# AT32F421xx register map
Vendor: Keil; Series: AT32F421; File version: 1.0
ARM 32-bit Cortex-M4 Microcontroller based device, CPU clock up to 120MHz, etc.
CPU: CM4 r0p1, little endian, no MPU, FPU, 4 interrupt priority bits
Registers are 32-bit, read-write, reset 0x0 unless marked. A register's access mark holds for its fields unless they carry their own. Offsets are from the block's base; lines under a group give offsets from that group; [hi:lo] are bit positions; {n}, {i} and the like mark numbered series; 'fields as' and 'values as' point back to an identical list; <NAME> marks a mode.

## Memory map
0x40000400 TMR3 size 0x400 — General purpose timer
0x40001000 TMR6 size 0x400 — Basic timer
0x40002000 TMR14 size 0x400 — General-purpose-timers
0x40002800 ERTC size 0x400 — Real-time clock
0x40002C00 WWDG size 0x400 — Window watchdog
0x40003000 IWDG size 0x400 — Independent watchdog
0x40003800 SPI2 size 0x400
0x40004400 USART2 size 0x400
0x40005400 I2C1 size 0x400 — Inter integrated circuit
0x40005800 I2C2 size 0x400
0x40007000 PWR size 0x400 — Power control
0x40010000 SYSCFG size 0x400 — System configuration controller
0x4001001C COMP size 0x400 — Compare
0x40010400 EXTI size 0x400
0x40012400 ADC1 size 0x400 — Analog to digital converter
0x40012C00 TMR1 size 0x400 — Advanced timer
0x40013000 SPI1 size 0x400 — Serial peripheral interface
0x40013800 USART1 size 0x400 — Universal synchronous asynchronous receiver transmitter
0x40014000 TMR15 size 0x400 — General-purpose-timers
0x40014400 TMR16 size 0x400 — General-purpose-timers
0x40014800 TMR17 size 0x400
0x40020000 DMA1 size 0x400 — DMA controller
0x40021000 RCC size 0x400 — Reset and clock control
0x40022000 EFC size 0x400
0x40023000 CRC size 0x400 — CRC calculation unit
0x48000000 GPIOA size 0x400 — General purpose I/Os
0x48000400 GPIOB size 0x400
0x48000800 GPIOC size 0x400
0x48001400 GPIOF size 0x400
0xE000E000 NVIC size 0x1001 — Nested Vectored Interrupt Controller
0xE0042000 MCUDBG size 0x400 — Debug support

## Interrupts
0 WWDG — Window Watchdog interrupt
1 PVD (PWR) — PVD through EXTI line detection interrupt
2 ERTC_WKUP (ERTC) — ERTC Global interrupt through the EXTI line17/19/21
3 EFLASH (EFC) — EFlash global interrupt
4 RCC — RCC global interrupt
5 EXTINT1_0 (EXTI) — EXTI Line1-0 interrupt
6 EXTINT3_2 (EXTI) — EXTI Line3-2 interrupt
7 EXTINT15_4 (EXTI) — EXTI Line15-4 interrupt
9 DMA1_Channel1 (DMA1) — DMA1 Channel1 global interrupt
10 DMA1_Channel3_2 (DMA1) — DMA1 Channel3-2 global interrupt
11 DMA1_Channel5_4 (DMA1) — DMA1 Channel5-4 global interrupt
12 ADC_COMP (ADC1, COMP) — ADC and COMP global interrupt
13 TMR1_BRK_UP_TRG_COM (TMR1) — TMR1 Break Update Trigger and Communication global
14 TIM1_CC (TMR1) — TMR1 Capture Compare interrupt
16 TMR3 — TMR3 global interrupt
17 TMR6 — TMR6 global interrupt
19 TMR14 — TMR14 global interrupt
20 TMR15 — TMR15 global interrupt
21 TMR16 — TMR16 global interrupt
22 TMR17 — TMR17 global interrupt
23 I2C1_EV (I2C1) — I2C1 event interrupt
24 I2C2_EV (I2C2) — I2C2 event interrupt
25 SPI1 — SPI1 global interrupt
26 SPI2 — SPI2 global interrupt
27 USART1 — USART1 global interrupt
28 USART2 — USART2 global interrupt
32 I2C1_ER (I2C1) — I2C1 error interrupt
34 I2C2_ER (I2C2) — I2C2 error interrupt

## PWR — Power control
Base 0x40007000
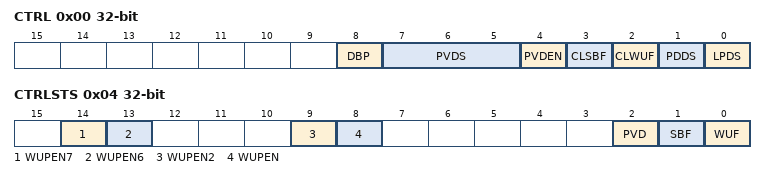
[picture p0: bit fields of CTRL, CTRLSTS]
0x00 CTRL — Power control register (PWR_CTRL)
  [8] DBP — Disable Backup Domain write protection
  [7:5] PVDS — PVD Level Selection
  [4] PVDEN — Power Voltage Detector Enable
  [3] CLSBF — Clear STANDBY Flag
  [2] CLWUF — Clear Wake-up Flag
  [1] PDDS — Power Down Deep Sleep
  [0] LPDS — Low Power Deep Sleep
0x04 CTRLSTS — Power control register (PWR_CTRLST)
  [14] WUPEN7 — Enable WKUP7 pin
  [13] WUPEN6 — Enable WKUP6 pin
  [9] WUPEN2 — Enable WKUP2 pin
  [8] WUPEN — Enable WKUP pin
  [2] PVD ro — PVD Output
  [1] SBF ro — STANDBY Flag
  [0] WUF ro — Wake-Up Flag
0x20 CTRL2 — Power control register 2 (PWR_CTRL2)
  [5] LPDS1 — Low Power Deep Sleep bit 1

## Licence text in the file
ARM Limited (ARM) is supplying this software for use with Cortex-M processor based microcontroller, but can be equally used for other suitable processor architectures. This file can be freely distributed. Modifications to this file shall be clearly marked. . THIS SOFTWARE IS PROVIDED "AS IS". NO WARRANTIES, WHETHER EXPRESS, IMPLIED. OR STATUTORY, INCLUDING, BUT NOT LIMITED TO, IMPLIED WARRANTIES OF. MERCHANTABILITY AND FITNESS FOR A PARTICULAR PURPOSE APPLY TO THIS SOFTWARE. ARM SHALL NOT, IN ANY CIRCUMSTANCES, BE LIABLE FOR SPECIAL, INCIDENTAL, OR. CONSEQUENTIAL DAMAGES, FOR ANY REASON WHATSOEVER.

## Notices in the file
Copyright (C) 2012-2014 ARM Limited. All rights reserved.
Purpose: System Viewer Description (SVD) Example (Schema Version 1.1)
This is a description of a none-existent and incomplete device
for demonstration purposes only.
Redistribution and use in source and binary forms, with or without
modification, are permitted provided that the following conditions are met:
- Redistributions of source code must retain the above copyright
notice, this list of conditions and the following disclaimer.
- Redistributions in binary form must reproduce the above copyright
notice, this list of conditions and the following disclaimer in the
documentation and/or other materials provided with the distribution.
- Neither the name of ARM nor the names of its contributors may be used
to endorse or promote products derived from this software without
specific prior written permission.
THIS SOFTWARE IS PROVIDED BY THE COPYRIGHT HOLDERS AND CONTRIBUTORS "AS IS"
AND ANY EXPRESS OR IMPLIED WARRANTIES, INCLUDING, BUT NOT LIMITED TO, THE
ARE DISCLAIMED. IN NO EVENT SHALL COPYRIGHT HOLDERS AND CONTRIBUTORS BE
LIABLE FOR ANY DIRECT, INDIRECT, INCIDENTAL, SPECIAL, EXEMPLARY, OR
CONSEQUENTIAL DAMAGES (INCLUDING, BUT NOT LIMITED TO, PROCUREMENT OF
SUBSTITUTE GOODS OR SERVICES; LOSS OF USE, DATA, OR PROFITS; OR BUSINESS
INTERRUPTION) HOWEVER CAUSED AND ON ANY THEORY OF LIABILITY, WHETHER IN
CONTRACT, STRICT LIABILITY, OR TORT (INCLUDING NEGLIGENCE OR OTHERWISE)
ARISING IN ANY WAY OUT OF THE USE OF THIS SOFTWARE, EVEN IF ADVISED OF THE
POSSIBILITY OF SUCH DAMAGE.
